# nrf54l09_enga_flpr register map
Vendor: Nordic Semiconductor; Series: nrf54l; File version: 1
Registers are 32-bit, read-write, reset 0x0 unless marked. A register's access mark holds for its fields unless they carry their own. Offsets are from the block's base; [hi:lo] are bit positions; lines under a group give offsets from that group; {n}, {i} and the like mark numbered series; 'fields as' and 'values as' point back to an identical list.

## GLOBAL_MEMCONF_NS — Memory configuration 0
Base 0x400CF000
Same registers: GLOBAL_MEMCONF_S 0x500CF000
{0x500+0x10*i} POWER[{i}] (i=0..1) group — Unspecified
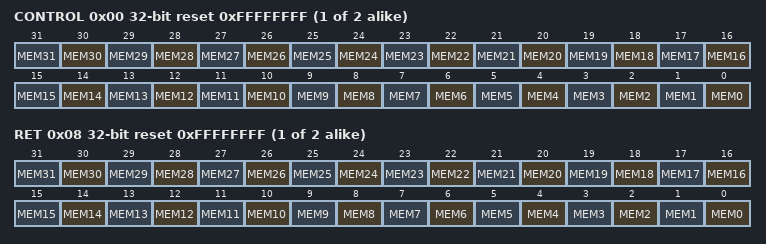
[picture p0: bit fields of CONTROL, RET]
  0x00 CONTROL reset 0xFFFFFFFF — Description cluster: Control memory block power.
    [all] fields
      0=Off (Power down); 1=On (Power up)
    [n] MEM{n} (n=0..31) — Keep the memory block MEM[{n}] on or off when in System ON mode.
  0x08 RET reset 0xFFFFFFFF — Description cluster: RAM retention for RAM [n].
    [all] fields
      0=Off (Retention off); 1=On (Retention on)
    [n] MEM{n} (n=0..31) — Keep the RAM block MEM[{n}] retained when in System OFF mode.

## GLOBAL_TEMP_NS — Temperature Sensor 0
Base 0x400D7000
Same registers: GLOBAL_TEMP_S 0x500D7000
0x00 TASKS_START wo — Start temperature measurement
  [0] TASKS_START
    1=Trigger task
0x04 TASKS_STOP wo — Stop temperature measurement
  [0] TASKS_STOP
    1=Trigger task
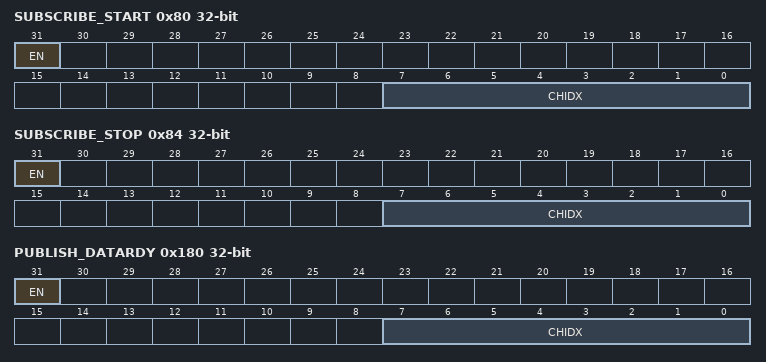
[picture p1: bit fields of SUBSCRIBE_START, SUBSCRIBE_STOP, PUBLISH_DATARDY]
0x80 SUBSCRIBE_START — Subscribe configuration for task START
  [31] EN
    0=Disabled (Disable subscription); 1=Enabled (Enable subscription)
  [7:0] CHIDX — DPPI channel that task START will subscribe to
0x84 SUBSCRIBE_STOP — Subscribe configuration for task STOP
  [31] EN
    values as SUBSCRIBE_START.EN
  [7:0] CHIDX — DPPI channel that task STOP will subscribe to
0x100 EVENTS_DATARDY — Temperature measurement complete, data ready
  [0] EVENTS_DATARDY
    0=NotGenerated (Event not generated); 1=Generated (Event generated)
0x180 PUBLISH_DATARDY — Publish configuration for event DATARDY
  [31] EN
    0=Disabled (Disable publishing); 1=Enabled (Enable publishing)
  [7:0] CHIDX — DPPI channel that event DATARDY will publish to
0x304 INTENSET — Enable interrupt
  [0] DATARDY — Write '1' to enable interrupt for event DATARDY
    on read: 0=Disabled (Read: Disabled); 1=Enabled (Read: Enabled) | on write: 1=Set (Enable)
0x308 INTENCLR — Disable interrupt
  [0] DATARDY — Write '1' to disable interrupt for event DATARDY
    on read: 0=Disabled (Read: Disabled); 1=Enabled (Read: Enabled) | on write: 1=Clear (Disable)
0x508 TEMP ro — Temperature in degC (0.25deg steps)
0x520 A0 reset 0x2D6 — Slope of 1st piece wise linear function
  [11:0] A0
0x524 A1 reset 0x32D — Slope of 2nd piece wise linear function
  [11:0] A1
0x528 A2 reset 0x384 — Slope of 3rd piece wise linear function
  [11:0] A2
0x52C A3 reset 0x3E9 — Slope of 4th piece wise linear function
  [11:0] A3
0x530 A4 reset 0x46F — Slope of 5th piece wise linear function
  [11:0] A4
0x534 A5 reset 0x522 — Slope of 6th piece wise linear function
  [11:0] A5
0x538 A6 reset 0x5B7 — Slope of 7th piece wise linear function
  [11:0] A6
0x540 B0 reset 0xFD6 — y-intercept of 1st piece wise linear function
  [11:0] B0
0x544 B1 reset 0xF76 — y-intercept of 2nd piece wise linear function
  [11:0] B1
0x548 B2 reset 0xF8A — y-intercept of 3rd piece wise linear function
  [11:0] B2
0x54C B3 reset 0xFF8 — y-intercept of 4th piece wise linear function
  [11:0] B3
0x550 B4 reset 0xCC — y-intercept of 5th piece wise linear function
  [11:0] B4
0x554 B5 reset 0x207 — y-intercept of 6th piece wise linear function
  [11:0] B5
0x558 B6 reset 0x558 — y-intercept of 7th piece wise linear function
  [11:0] B6
0x560 T0 reset 0xE2 — End point of 1st piece wise linear function
  [7:0] T0
0x564 T1 reset 0x2 — End point of 2nd piece wise linear function
  [7:0] T1
0x568 T2 reset 0x1F — End point of 3rd piece wise linear function
  [7:0] T2
0x56C T3 reset 0x38 — End point of 4th piece wise linear function
  [7:0] T3
0x570 T4 reset 0x4F — End point of 5th piece wise linear function
  [7:0] T4
0x574 T5 reset 0x66 — End point of 6th piece wise linear function
  [7:0] T5

## GLOBAL_P1_NS — GPIO Port 0
Base 0x400D8200
Same registers: GLOBAL_P0_NS 0x4010A000, GLOBAL_P1_S 0x500D8200, GLOBAL_P0_S 0x5010A000
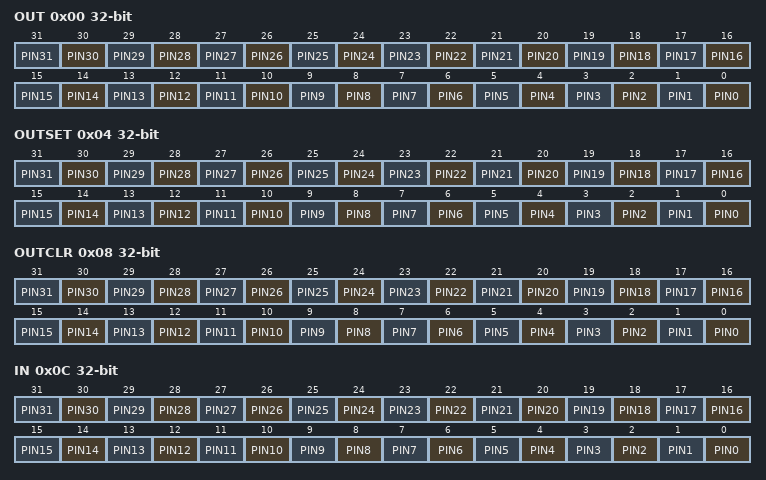
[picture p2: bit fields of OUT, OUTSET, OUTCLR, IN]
0x00 OUT — Write GPIO port
  [all] fields
    0=Low (Pin driver is low); 1=High (Pin driver is high)
  [n] PIN{n} (n=0..31)
0x04 OUTSET write-1-sets — Set individual bits in GPIO port
  [all] fields
    on read: 0=Low (Read: pin driver is low); 1=High (Read: pin driver is high) | on write: 1=Set (Write: writing a '1' sets the pin high; writing a '0' has no effect)
  [n] PIN{n} (n=0..31)
0x08 OUTCLR write-1-clears — Clear individual bits in GPIO port
  [all] fields
    on read: 0=Low (Read: pin driver is low); 1=High (Read: pin driver is high) | on write: 1=Clear (Write: writing a '1' sets the pin low; writing a '0' has no effect)
  [n] PIN{n} (n=0..31)
0x0C IN ro — Read GPIO port
  [all] fields
    0=Low (Pin input is low); 1=High (Pin input is high)
  [n] PIN{n} (n=0..31)
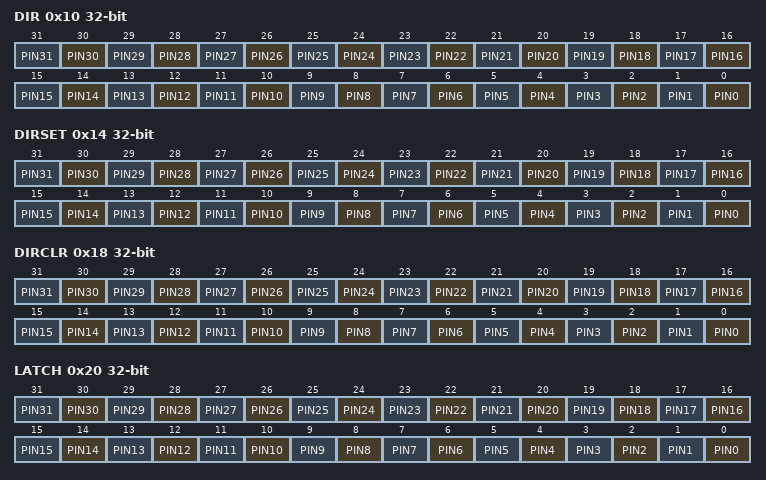
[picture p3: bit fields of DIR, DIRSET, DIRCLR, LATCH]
0x10 DIR — Direction of GPIO pins
  [all] fields
    0=Input (Pin set as input); 1=Output (Pin set as output)
  [n] PIN{n} (n=0..31)
0x14 DIRSET write-1-sets
  [all] fields
    on read: 0=Input (Read: pin set as input); 1=Output (Read: pin set as output) | on write: 1=Set (Write: writing a '1' sets pin to output; writing a '0' has no effect)
  [n] PIN{n} (n=0..31) — Set as output pin {n}
0x18 DIRCLR write-1-clears — DIR clear register
  [all] fields
    on read: 0=Input (Read: pin set as input); 1=Output (Read: pin set as output) | on write: 1=Clear (Write: writing a '1' sets pin to input; writing a '0' has no effect)
  [n] PIN{n} (n=0..31) — Set as input pin {n}
0x20 LATCH — Latch register indicating what GPIO pins that have met the criteria set in the PIN_CNF[n].SENSE registers
  [all] fields
    0=NotLatched (Criteria has not been met); 1=Latched (Criteria has been met)
  [n] PIN{n} (n=0..31) — Status on whether PIN{n} has met criteria set in PIN_CNF[{n}].SENSE register. Write '1' to clear.
0x24 DETECTMODE — Select between default DETECT signal behavior and LDETECT mode
  [0] DETECTMODE
    0=Default (DETECT directly connected to PIN DETECT signals); 1=LDETECT (Use the latched LDETECT behavior)
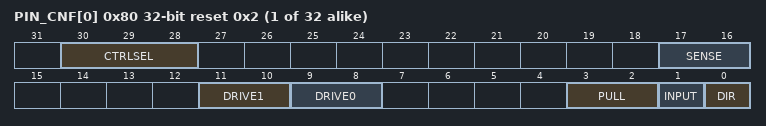
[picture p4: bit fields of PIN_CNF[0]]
{0x80+4i} PIN_CNF[{i}] (i=0..31) reset 0x2 — Description collection: Pin n configuration of GPIO pin
  [30:28] CTRLSEL — Select which module has direct control over this pin
    0=GPIO (GPIO or peripherals with PSEL registers); 1=VPR (VPR processor); 4=GRTC (GRTC peripheral)
  [17:16] SENSE — Pin sensing mechanism
    0=Disabled; 2=High (Sense for high level); 3=Low (Sense for low level)
  [11:10] DRIVE1 — Drive configuration for '1'
    0=S1 (Standard '1'); 1=H1 (High drive '1'); 2=D1 (Disconnect '1'(normally used for wired-or connections)); 3=E1 (Extra high drive '1')
  [9:8] DRIVE0 — Drive configuration for '0'
    0=S0 (Standard '0'); 1=H0 (High drive '0'); 2=D0 (Disconnect '0'(normally used for wired-or connections)); 3=E0 (Extra high drive '0')
  [3:2] PULL — Pull configuration
    0=Disabled (No pull); 1=Pull down on pin; 3=Pull up on pin
  [1] INPUT — Connect or disconnect input buffer
    0=Connect input buffer; 1=Disconnect input buffer
  [0] DIR — Pin direction. Same physical register as DIR register
    0=Input (Configure pin as an input pin); 1=Output (Configure pin as an output pin)
